VERSION ""

NS_ :

BS_:

BU_: ECU1 ECU2 ECU3

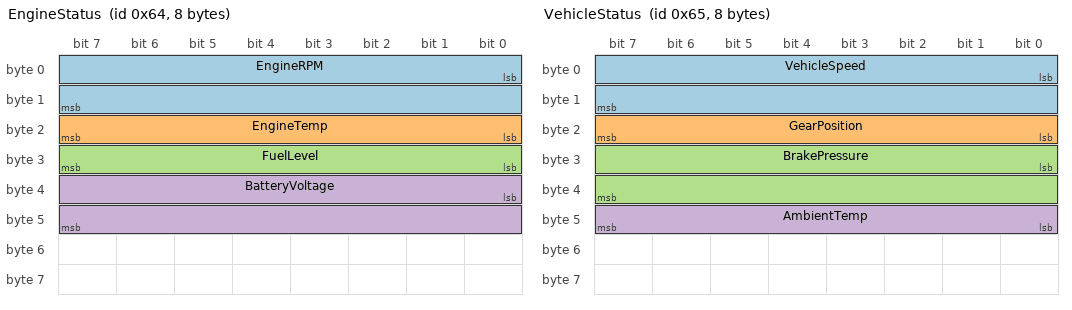
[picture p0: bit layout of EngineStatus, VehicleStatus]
BO_ 100 EngineStatus: 8 ECU1
 SG_ EngineRPM : 0|16@1+ (0.25,0) [0|16000] "rpm" ECU2,ECU3
 SG_ EngineTemp : 16|8@1+ (1,-40) [-40|215] "C" ECU2,ECU3
 SG_ FuelLevel : 24|8@1+ (0.4,0) [0|100] "%" ECU2,ECU3
 SG_ BatteryVoltage : 32|16@1+ (0.01,0) [0|655.35] "V" ECU2,ECU3

BO_ 101 VehicleStatus: 8 ECU1
 SG_ VehicleSpeed : 0|16@1+ (0.01,0) [0|655.35] "km/h" ECU2,ECU3
 SG_ GearPosition : 16|8@1+ (1,0) [0|6] "" ECU2,ECU3
 SG_ BrakePressure : 24|16@1+ (0.015625,0) [0|1000] "bar" ECU2,ECU3
 SG_ AmbientTemp : 40|8@1+ (1,-40) [-40|100] "C" ECU2,ECU3

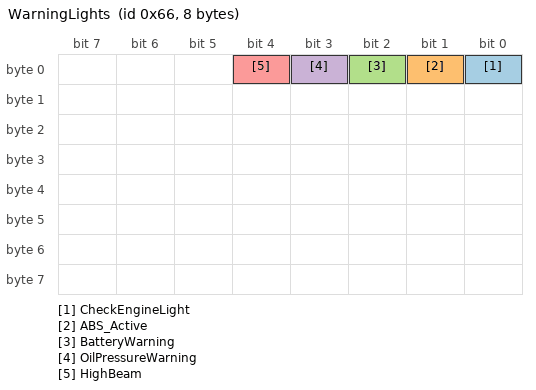
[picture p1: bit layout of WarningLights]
BO_ 102 WarningLights: 8 ECU1
 SG_ CheckEngineLight : 0|1@1+ (1,0) [0|1] "" ECU2,ECU3
 SG_ ABS_Active : 1|1@1+ (1,0) [0|1] "" ECU2,ECU3
 SG_ BatteryWarning : 2|1@1+ (1,0) [0|1] "" ECU2,ECU3
 SG_ OilPressureWarning : 3|1@1+ (1,0) [0|1] "" ECU2,ECU3
 SG_ HighBeam : 4|1@1+ (1,0) [0|1] "" ECU2,ECU3

VAL_ 101 GearPosition 0 "P" 1 "R" 2 "N" 3 "D" 4 "S" 5 "L" ;

BA_DEF_ BO_ "GenMsgCycleTime" INT 0 10000;

BA_ "GenMsgCycleTime" BO_ 100 50;
BA_ "GenMsgCycleTime" BO_ 101 100;
BA_ "GenMsgCycleTime" BO_ 102 100;
